AUTOSAR XML (schema 00044)
package /E40_Platform_System_SystemPackage/Components
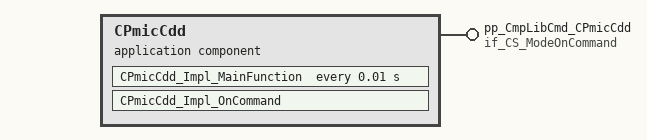
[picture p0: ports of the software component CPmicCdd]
  application sw component type CPmicCdd
    provide port pp_CmpLibCmd_CPmicCdd: server-com-spec{operation=Impl_OnCommand, queue-length=1}, provided-interface=if_CS_ModeOnCommand
    behavior IB_CPmicCdd: port-api-option{enable-take-address=false, indirect-api=false, port=pp_CmpLibCmd_CPmicCdd}
      operation invoked event OIE_pp_CmpLibCmd_CPmicCdd_CPmicCdd_Impl_OnCommandTrigByImpl_OnCommand: start-on-event=CPmicCdd_Impl_OnCommand, operation=pp_CmpLibCmd_CPmicCdd.Impl_OnCommand
      timing event TECPmicCdd_Impl_MainFunction: start-on-event=CPmicCdd_Impl_MainFunction, period=0.01
      runnable CPmicCdd_Impl_OnCommand: can-be-invoked-concurrently=true
      runnable CPmicCdd_Impl_MainFunction: can-be-invoked-concurrently=true
  swc implementation IMPL_CPmicCdd: behavior=IB_CPmicCdd
